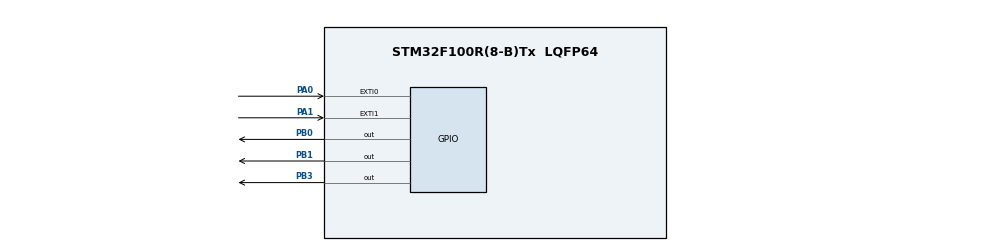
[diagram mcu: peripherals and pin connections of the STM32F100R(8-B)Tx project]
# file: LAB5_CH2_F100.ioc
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Mcu.Family=STM32F1
Mcu.Name=STM32F100R(8-B)Tx
Mcu.Package=LQFP64
NVIC.EXTI0_IRQn=true\:0\:0\:false\:false\:true\:true\:true
NVIC.EXTI1_IRQn=true\:0\:0\:false\:false\:true\:true\:true
NVIC.PriorityGroup=NVIC_PRIORITYGROUP_4
NVIC.TIM6_DAC_IRQn=true\:0\:0\:false\:false\:true\:true\:true
PA0-WKUP.GPIO_PuPd=GPIO_PULLUP
PA0-WKUP.Signal=GPXTI0
PA1.GPIO_PuPd=GPIO_PULLUP
PA1.Signal=GPXTI1
PA13.Mode=Serial_Wire
PA13.Signal=SYS_JTMS-SWDIO
PA14.Mode=Serial_Wire
PA14.Signal=SYS_JTCK-SWCLK
PB0.GPIO_ModeDefaultOutputPP=GPIO_MODE_OUTPUT_OD
PB0.PinState=GPIO_PIN_SET
PB0.Signal=GPIO_Output
PB1.GPIO_ModeDefaultOutputPP=GPIO_MODE_OUTPUT_OD
PB1.PinState=GPIO_PIN_SET
PB1.Signal=GPIO_Output
PB3.GPIO_ModeDefaultOutputPP=GPIO_MODE_OUTPUT_OD
PB3.PinState=GPIO_PIN_SET
PB3.Signal=GPIO_Output
PC14-OSC32_IN.Mode=LSE-External-Oscillator
PC14-OSC32_IN.Signal=RCC_OSC32_IN
PC15-OSC32_OUT.Mode=LSE-External-Oscillator
PC15-OSC32_OUT.Signal=RCC_OSC32_OUT
PD0-OSC_IN.Mode=HSE-External-Oscillator
PD0-OSC_IN.Signal=RCC_OSC_IN
PD1-OSC_OUT.Mode=HSE-External-Oscillator
PD1-OSC_OUT.Signal=RCC_OSC_OUT
ProjectManager.HeapSize=0x200
ProjectManager.StackSize=0x400
ProjectManager.TargetToolchain=EWARM V8
RCC.AHBFreq_Value=8000000
RCC.APB1Freq_Value=8000000
RCC.APB1TimFreq_Value=8000000
RCC.APB2Freq_Value=8000000
RCC.APB2TimFreq_Value=8000000
RCC.HCLKFreq_Value=8000000
RCC.SYSCLKFreq_VALUE=8000000
TIM1.TIM_MasterOutputTrigger=TIM_TRGO_ENABLE
TIM6.Period=1000
TIM6.Prescaler=7999
VP_RTC_VS_RTC_Activate.Mode=RTC_Enabled
VP_TIM1_VS_ClockSourceINT.Mode=Internal
VP_TIM6_VS_ClockSourceINT.Mode=Enable_Timer
board=custom

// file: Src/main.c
/* USER CODE BEGIN Header */
/**
  ******************************************************************************
  * @file           : main.c
  * @brief          : Main program body
  ******************************************************************************
  * @attention
  *
  * <h2><center>&copy; Copyright (c) 2019 STMicroelectronics.
  * All rights reserved.</center></h2>
  *
  * This software component is licensed by ST under BSD 3-Clause license,
  * the "License"; You may not use this file except in compliance with the
  * License. You may obtain a copy of the License at:
  *                        opensource.org/licenses/BSD-3-Clause
  *
  ******************************************************************************
  */
/* USER CODE END Header */

#include "main.h"

RTC_HandleTypeDef hrtc;

TIM_HandleTypeDef htim1;

void SystemClock_Config(void);
static void MX_GPIO_Init(void);
static void MX_TIM6_Init(void);
static void MX_RTC_Init(void);
static void MX_TIM1_Init(void);

int main(void)
{

  /* MCU Configuration--------------------------------------------------------*/

  /* Reset of all peripherals, Initializes the Flash interface and the Systick. */
  HAL_Init();

  /* Configure the system clock */
  SystemClock_Config();

  /* Initialize all configured peripherals */
  MX_GPIO_Init();
  MX_TIM6_Init();
  MX_RTC_Init();
  MX_TIM1_Init();
  /* USER CODE BEGIN 2 */
LL_TIM_EnableIT_UPDATE(TIM6); // ????????? ?????????? ? TIM6
  LL_TIM_EnableCounter(TIM6); // ???????? TIM6
  /* USER CODE END 2 */

  /* Infinite loop */
  while (1)
  {

  }
}

void SystemClock_Config(void)
{
  LL_RCC_HSI_SetCalibTrimming(16);
  LL_RCC_HSI_Enable();

   /* Wait till HSI is ready */
  while(LL_RCC_HSI_IsReady() != 1)
  {

  }
  LL_RCC_LSI_Enable();

   /* Wait till LSI is ready */
  while(LL_RCC_LSI_IsReady() != 1)
  {

  }
  LL_PWR_EnableBkUpAccess();
  LL_RCC_ForceBackupDomainReset();
  LL_RCC_ReleaseBackupDomainReset();
  LL_RCC_SetRTCClockSource(LL_RCC_RTC_CLKSOURCE_LSI);
  LL_RCC_EnableRTC();
  LL_RCC_SetAHBPrescaler(LL_RCC_SYSCLK_DIV_1);
  LL_RCC_SetAPB1Prescaler(LL_RCC_APB1_DIV_1);
  LL_RCC_SetAPB2Prescaler(LL_RCC_APB2_DIV_1);
  LL_RCC_SetSysClkSource(LL_RCC_SYS_CLKSOURCE_HSI);

   /* Wait till System clock is ready */
  while(LL_RCC_GetSysClkSource() != LL_RCC_SYS_CLKSOURCE_STATUS_HSI)
  {

  }
  LL_Init1msTick(8000000);
  LL_SYSTICK_SetClkSource(LL_SYSTICK_CLKSOURCE_HCLK);
  LL_SetSystemCoreClock(8000000);
}

static void MX_RTC_Init(void)
{

  /** Initialize RTC Only
  */
  hrtc.Instance = RTC;
  hrtc.Init.AsynchPrediv = RTC_AUTO_1_SECOND;
  hrtc.Init.OutPut = RTC_OUTPUTSOURCE_ALARM;
  if (HAL_RTC_Init(&hrtc) != HAL_OK)
  {
    Error_Handler();
  }

}

static void MX_TIM1_Init(void)
{

  TIM_ClockConfigTypeDef sClockSourceConfig = {0};
  TIM_MasterConfigTypeDef sMasterConfig = {0};

  htim1.Instance = TIM1;
  htim1.Init.Prescaler = 0;
  htim1.Init.CounterMode = TIM_COUNTERMODE_UP;
  htim1.Init.Period = 0;
  htim1.Init.ClockDivision = TIM_CLOCKDIVISION_DIV1;
  htim1.Init.RepetitionCounter = 0;
  htim1.Init.AutoReloadPreload = TIM_AUTORELOAD_PRELOAD_DISABLE;
  if (HAL_TIM_Base_Init(&htim1) != HAL_OK)
  {
    Error_Handler();
  }
  sClockSourceConfig.ClockSource = TIM_CLOCKSOURCE_INTERNAL;
  if (HAL_TIM_ConfigClockSource(&htim1, &sClockSourceConfig) != HAL_OK)
  {
    Error_Handler();
  }
  sMasterConfig.MasterOutputTrigger = TIM_TRGO_ENABLE;
  sMasterConfig.MasterSlaveMode = TIM_MASTERSLAVEMODE_DISABLE;
  if (HAL_TIMEx_MasterConfigSynchronization(&htim1, &sMasterConfig) != HAL_OK)
  {
    Error_Handler();
  }

}

static void MX_TIM6_Init(void)
{

  LL_TIM_InitTypeDef TIM_InitStruct = {0};

  /* Peripheral clock enable */
  LL_APB1_GRP1_EnableClock(LL_APB1_GRP1_PERIPH_TIM6);

  /* TIM6 interrupt Init */
  NVIC_SetPriority(TIM6_DAC_IRQn, NVIC_EncodePriority(NVIC_GetPriorityGrouping(),0, 0));
  NVIC_EnableIRQ(TIM6_DAC_IRQn);

  TIM_InitStruct.Prescaler = 7999;
  TIM_InitStruct.CounterMode = LL_TIM_COUNTERMODE_UP;
  TIM_InitStruct.Autoreload = 1000;
  LL_TIM_Init(TIM6, &TIM_InitStruct);
  LL_TIM_DisableARRPreload(TIM6);
  LL_TIM_SetTriggerOutput(TIM6, LL_TIM_TRGO_RESET);
  LL_TIM_DisableMasterSlaveMode(TIM6);

}

static void MX_GPIO_Init(void)
{
  GPIO_InitTypeDef GPIO_InitStruct = {0};

  /* GPIO Ports Clock Enable */
  __HAL_RCC_GPIOC_CLK_ENABLE();
  __HAL_RCC_GPIOD_CLK_ENABLE();
  __HAL_RCC_GPIOA_CLK_ENABLE();
  __HAL_RCC_GPIOB_CLK_ENABLE();

  /*Configure GPIO pin Output Level */
  HAL_GPIO_WritePin(GPIOB, GPIO_PIN_0|GPIO_PIN_1|GPIO_PIN_3, GPIO_PIN_SET);

  /*Configure GPIO pins : PA0 PA1 */
  GPIO_InitStruct.Pin = GPIO_PIN_0|GPIO_PIN_1;
  GPIO_InitStruct.Mode = GPIO_MODE_IT_RISING;
  GPIO_InitStruct.Pull = GPIO_PULLUP;
  HAL_GPIO_Init(GPIOA, &GPIO_InitStruct);

  /*Configure GPIO pins : PB0 PB1 PB3 */
  GPIO_InitStruct.Pin = GPIO_PIN_0|GPIO_PIN_1|GPIO_PIN_3;
  GPIO_InitStruct.Mode = GPIO_MODE_OUTPUT_OD;
  GPIO_InitStruct.Pull = GPIO_NOPULL;
  GPIO_InitStruct.Speed = GPIO_SPEED_FREQ_LOW;
  HAL_GPIO_Init(GPIOB, &GPIO_InitStruct);

  /* EXTI interrupt init*/
  HAL_NVIC_SetPriority(EXTI0_IRQn, 0, 0);
  HAL_NVIC_EnableIRQ(EXTI0_IRQn);

  HAL_NVIC_SetPriority(EXTI1_IRQn, 0, 0);
  HAL_NVIC_EnableIRQ(EXTI1_IRQn);

}

void Error_Handler(void)
{
}

/************************ (C) COPYRIGHT STMicroelectronics *****END OF FILE****/
